# CC1312PSIP register map
File version: 1.0
CPU: CM4 1.0, other endian, MPU, FPU, 3 interrupt priority bits
Registers are 32-bit, read-write, reset 0x0 unless marked. A register's access mark holds for its fields unless they carry their own. Offsets are from the block's base; [hi:lo] are bit positions.

## TRNG — True Random Number Generator
Base 0x40028000
0x00 OUT0 — Random Number Lower Word Readout Value
  [31:0] VALUE_31_0 ro — [31:0] LSW of 64- bit random value. New value ready when IRQFLAGSTAT.RDY = 1.
0x04 OUT1 — Random Number Upper Word Readout Value
  [31:0] VALUE_63_32 ro — [31:0] MSW of 64-bit random value. New value ready when IRQFLAGSTAT.RDY = 1.
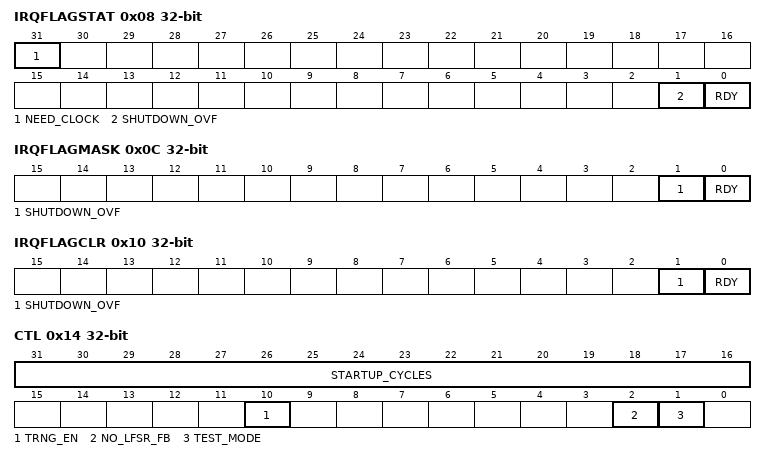
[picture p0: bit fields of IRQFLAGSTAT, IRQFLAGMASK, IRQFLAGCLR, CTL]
0x08 IRQFLAGSTAT — Interrupt Status
  [31] NEED_CLOCK ro — [31:31] 1: Indicates that the TRNG is busy generating entropy or is in one of its test modes - clocks may not be turned off and the power supply voltage must be kept stable. 0: TRNG is idle and can be shut down
  [1] SHUTDOWN_OVF ro — [1:1] 1: The number of FROs shut down (i.e. the number of '1' bits in the ALARMSTOP register) has exceeded the threshold set by ALARMCNT.SHUTDOWN_THR Writing '1' to IRQFLAGCLR.SHUTDOWN_OVF clears this bit to '0' again.
  [0] RDY ro — [0:0] 1: Data are available in OUT0 and OUT1. Acknowledging this state by writing '1' to IRQFLAGCLR.RDY clears this bit to '0'. If a new number is already available in the internal register of the TRNG, the number is directly clocked into the result register. In this case the status bit is asserted again, after one clock cycle.
0x0C IRQFLAGMASK — Interrupt Mask
  [1] SHUTDOWN_OVF — [1:1] 1: Allow IRQFLAGSTAT.SHUTDOWN_OVF to activate the interrupt from this module.
  [0] RDY — [0:0] 1: Allow IRQFLAGSTAT.RDY to activate the interrupt from this module.
0x10 IRQFLAGCLR — Interrupt Flag Clear
  [1] SHUTDOWN_OVF wo — [1:1] 1: Clear IRQFLAGSTAT.SHUTDOWN_OVF.
  [0] RDY wo — [0:0] 1: Clear IRQFLAGSTAT.RDY.
0x14 CTL — Control
  [31:16] STARTUP_CYCLES — [31:16] This field determines the number of samples (between 2^8 and 2^24) taken to gather entropy from the FROs during startup. If the written value of this field is zero, the number of samples is 2^24, otherwise the number of samples equals the written value times 2^8. 0x0000: 2^24 samples 0x0001: 1*2^8 samples 0x0002: 2*2^8 samples 0x0003: 3*2^8 samples ... 0x8000: 32768*2^8 samples 0xC000: 49152*2^8 samples ... 0xFFFF: 65535*2^8 samples This field can only be modified while TRNG_EN is 0. If 1 an update will be ignored.
  [10] TRNG_EN — [10:10] 0: Forces all TRNG logic back into the idle state immediately. 1: Starts TRNG, gathering entropy from the FROs for the number of samples determined by STARTUP_CYCLES.
  [2] NO_LFSR_FB — [2:2] 1: Remove XNOR feedback from the main LFSR, converting it into a normal shift register for the XOR-ed outputs of the FROs (shifting data in on the LSB side). A '1' also forces the LFSR to sample continuously. This bit can only be set to '1' when TEST_MODE is also set to '1' and should not be used for other than test purposes
  [1] TEST_MODE — [1:1] 1: Enables access to the TESTCNT and LFSR0/LFSR1/LFSR2 registers (the latter are automatically cleared before enabling access) and keeps IRQFLAGSTAT.NEED_CLOCK at '1'. This bit shall not be used unless you need to change the LFSR seed prior to creating a new random value. All other testing is done external to register control.
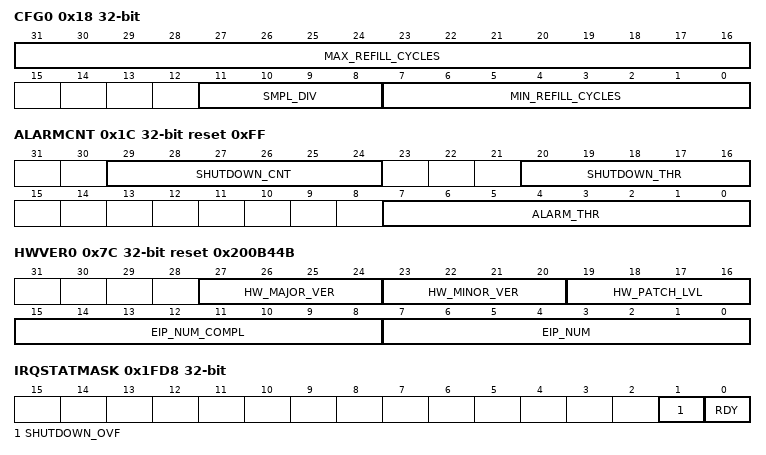
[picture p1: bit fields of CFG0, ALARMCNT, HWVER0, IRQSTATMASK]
0x18 CFG0 — Configuration 0
  [31:16] MAX_REFILL_CYCLES — [31:16] This field determines the maximum number of samples (between 2^8 and 2^24) taken to re-generate entropy from the FROs after reading out a 64 bits random number. If the written value of this field is zero, the number of samples is 2^24, otherwise the number of samples equals the written value times 2^8. 0x0000: 2^24 samples 0x0001: 1*2^8 samples 0x0002: 2*2^8 samples 0x0003: 3*2^8 samples ... 0x8000: 32768*2^8 samples 0xC000: 49152*2^8 samples ... 0xFFFF: 65535*2^8 samples This field can only be modified while CTL.TRNG_EN is 0.
  [11:8] SMPL_DIV — [11:8] This field directly controls the number of clock cycles between samples taken from the FROs. Default value 0 indicates that samples are taken every clock cycle, maximum value 0xF takes one sample every 16 clock cycles. This field must be set to a value such that the slowest FRO (even under worst-case conditions) has a cycle time less than twice the sample period. This field can only be modified while CTL.TRNG_EN is '0'.
  [7:0] MIN_REFILL_CYCLES — [7:0] This field determines the minimum number of samples (between 2^6 and 2^14) taken to re-generate entropy from the FROs after reading out a 64 bits random number. If the value of this field is zero, the number of samples is fixed to the value determined by the MAX_REFILL_CYCLES field, otherwise the minimum number of samples equals the written value times 64 (which can be up to 2^14). To ensure same entropy in all generated random numbers the value 0 should be used. Then MAX_REFILL_CYCLES controls the minimum refill interval. The number of samples defined here cannot be higher than the number defined by the 'max_refill_cycles' field (i.e. that field takes precedence). No random value will be created if min refill > max refill. This field can only be modified while CTL.TRNG_EN = 0. 0x00: Minimum samples = MAX_REFILL_CYCLES (all numbers have same entropy) 0x01: 1*2^6 samples 0x02: 2*2^6 samples ... 0xFF: 255*2^6 samples
0x1C ALARMCNT reset 0xFF — Alarm Control
  [29:24] SHUTDOWN_CNT — [29:24] Read-only, indicates the number of '1' bits in ALARMSTOP register. The maximum value equals the number of FROs.
  [20:16] SHUTDOWN_THR — [20:16] Threshold setting for generating IRQFLAGSTAT.SHUTDOWN_OVF interrupt. The interrupt is triggered when SHUTDOWN_CNT value exceeds this bit field.
  [7:0] ALARM_THR — [7:0] Alarm detection threshold for the repeating pattern detectors on each FRO. An FRO 'alarm event' is declared when a repeating pattern (of up to four samples length) is detected continuously for the number of samples defined by this field's value. Reset value 0xFF should keep the number of 'alarm events' to a manageable level.
0x20 FROEN reset 0xFFFFFF — FRO Enable
  [23:0] FRO_MASK — [23:0] Enable bits for the individual FROs. A '1' in bit [n] enables FRO 'n'. Default state is all '1's to enable all FROs after power-up. Note that they are not actually started up before the CTL.TRNG_EN bit is set to '1'. Bits are automatically forced to '0' here (and cannot be written to '1') while the corresponding bit in ALARMSTOP.FRO_FLAGS has value '1'.
0x24 FRODETUNE — FRO De-tune Bit
  [23:0] FRO_MASK — [23:0] De-tune bits for the individual FROs. A '1' in bit [n] lets FRO 'n' run approximately 5% faster. The value of one of these bits may only be changed while the corresponding FRO is turned off (by temporarily writing a '0' in the corresponding bit of the FROEN.FRO_MASK register).
0x28 ALARMMASK — Alarm Event
  [23:0] FRO_MASK — [23:0] Logging bits for the 'alarm events' of individual FROs. A '1' in bit [n] indicates FRO 'n' experienced an 'alarm event'.
0x2C ALARMSTOP — Alarm Shutdown
  [23:0] FRO_FLAGS — [23:0] Logging bits for the 'alarm events' of individual FROs. A '1' in bit [n] indicates FRO 'n' experienced more than one 'alarm event' in quick succession and has been turned off. A '1' in this field forces the corresponding bit in FROEN.FRO_MASK to '0'.
0x30 LFSR0 — LFSR Readout Value
  [31:0] LFSR_31_0 — [31:0] Bits [31:0] of the main entropy accumulation LFSR. Register can only be accessed when CTL.TEST_MODE = 1. Register contents will be cleared to zero before access is enabled.
0x34 LFSR1 — LFSR Readout Value
  [31:0] LFSR_63_32 — [31:0] Bits [63:32] of the main entropy accumulation LFSR. Register can only be accessed when CTL.TEST_MODE = 1. Register contents will be cleared to zero before access is enabled.
0x38 LFSR2 — LFSR Readout Value
  [16:0] LFSR_80_64 — [16:0] Bits [80:64] of the main entropy accumulation LFSR. Register can only be accessed when CTL.TEST_MODE = 1. Register contents will be cleared to zero before access is enabled.
0x78 HWOPT reset 0x600 — TRNG Engine Options Information
  [11:6] NR_OF_FROS ro — [11:6] Number of FROs implemented in this TRNG, value 24 (decimal).
0x7C HWVER0 reset 0x200B44B — HW Version 0 EIP Number And Core Revision
  [27:24] HW_MAJOR_VER ro — [27:24] 4 bits binary encoding of the major hardware revision number.
  [23:20] HW_MINOR_VER ro — [23:20] 4 bits binary encoding of the minor hardware revision number.
  [19:16] HW_PATCH_LVL ro — [19:16] 4 bits binary encoding of the hardware patch level, initial release will carry value zero.
  [15:8] EIP_NUM_COMPL ro — [15:8] Bit-by-bit logic complement of bits [7:0]. This TRNG gives 0xB4.
  [7:0] EIP_NUM ro — [7:0] 8 bits binary encoding of the module number. This TRNG gives 0x4B.
0x1FD8 IRQSTATMASK — Interrupt Status After Masking
  [1] SHUTDOWN_OVF ro — [1:1] Shutdown Overflow (result of IRQFLAGSTAT.SHUTDOWN_OVF AND'ed with IRQFLAGMASK.SHUTDOWN_OVF)
  [0] RDY ro — [0:0] New random value available (result of IRQFLAGSTAT.RDY AND'ed with IRQFLAGMASK.RDY)
0x1FE0 HWVER1 reset 0x20 — HW Version 1 TRNG Revision Number
  [7:0] REV ro — [7:0] The revision number of this module is Rev 2.0.
0x1FEC IRQSET — Interrupt Set
  [31:0] RDY — [31:0] Software should not rely on the value of a reserved. Writing any other value than the reset value may result in undefined behavior.
0x1FF0 SWRESET — SW Reset Control
  [0] RESET — [0:0] Write '1' to soft reset , reset will be low for 4-5 clock cycles. Poll to 0 for reset to be completed.
0x1FF8 IRQSTAT — Interrupt Status
  [0] STAT ro — [0:0] TRNG Interrupt status. OR'ed version of IRQFLAGSTAT.SHUTDOWN_OVF and IRQFLAGSTAT.RDY
